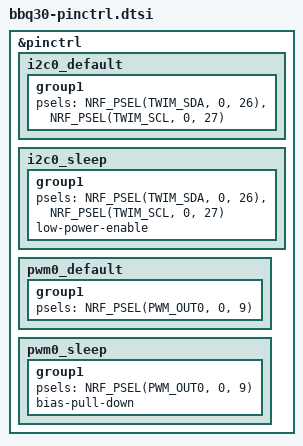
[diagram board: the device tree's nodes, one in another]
/*
 * Copyright (c) 2025 ZitaoTech
 * SPDX-License-Identifier: MIT
 */

&pinctrl {
    i2c0_default: i2c0_default {
        group1 {
            psels = <NRF_PSEL(TWIM_SDA, 0, 26)>,
                <NRF_PSEL(TWIM_SCL, 0, 27)>;
        };
    };

    i2c0_sleep: i2c0_sleep {
        group1 {
            psels = <NRF_PSEL(TWIM_SDA, 0, 26)>,
                <NRF_PSEL(TWIM_SCL, 0, 27)>;
            low-power-enable;
        };
    };


    pwm0_default:pwm0_default{
        group1{
            psels = <NRF_PSEL(PWM_OUT0, 0, 9)>; // Backlight for backlight.c unreal
        };
    };

    pwm0_sleep: pwm0_sleep {
        group1 {
            psels = <NRF_PSEL(PWM_OUT0, 0, 9)>;
            bias-pull-down;
        };
    };

};
